# ADuCM410 register map
Vendor: Analog Devices; Series: ADuCM410; File version: 1p0
CPU: CM33 r0p1, little endian, MPU, FPU, 3 interrupt priority bits
Registers are 32-bit, read-write, reset 0x0 unless marked. A register's access mark holds for its fields unless they carry their own. Offsets are from the block's base; [hi:lo] are bit positions; {n}, {i} and the like mark numbered series; 'fields as' and 'values as' point back to an identical list.

## DMAREQ
Base 0x40007000
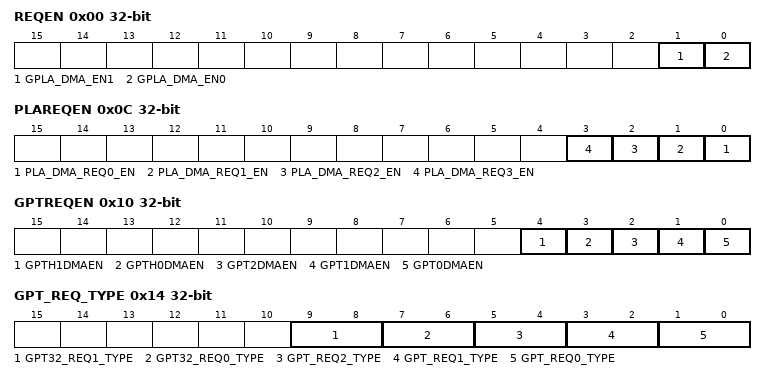
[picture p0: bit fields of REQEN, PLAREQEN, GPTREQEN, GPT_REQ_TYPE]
0x00 REQEN — GPT/GPT32 and PLA DMA Request Enable
  [1] GPLA_DMA_EN1 range 0x00000000..0x00000001 — GPT/GPT32 and PLA DMA Request 1 Enable
  [0] GPLA_DMA_EN0 range 0x00000000..0x00000001 — GPT/GPT32 and PLA DMA Request 0 Enable
0x04 REQ0SEL — GPT/GPT32 and PLA DMA Request 0 Select
  [3:0] DMA_REQ0_SEL — GPT/GPT32 and PLA DMA Request 0 Source Select
    {v}=PLA_REQ{v} (PLA DMA Request {v}) (v=0..3); 4=GPT_REQ0 (GPT 0 DMA Request); 5=GPT_REQ1 (GPT 1 DMA Request); 6=GPT_REQ2 (GPT 2 DMA Request); 7=GPt32_REQ0 (GPT32 0 DMA Request); 8=GPT32_REQ1 (GPT32 1 DMA Request)
0x08 REQ1SEL — GPT/GPT32 and PLA DMA Request 1 Select
  [3:0] DMA_REQ1_SEL — GPT/GPT32 and PLA DMA Request 1 Source Select
    values as REQ0SEL.DMA_REQ0_SEL
0x0C PLAREQEN — PLA DMA Requests Enable
  [n] PLA_DMA_REQ{n}_EN range 0x00000000..0x00000001 (n=0..3) — PLA DMA Request {n} Enable
0x10 GPTREQEN — GPT/GPT32 DMA Requests Enable
  [4] GPTH1DMAEN range 0x00000000..0x00000001 — GPT32 1 DMA Request Enable
  [3] GPTH0DMAEN range 0x00000000..0x00000001 — GPT32 0 DMA Request Enable
  [2] GPT2DMAEN range 0x00000000..0x00000001 — GPT 2 DMA Request Enable
  [1] GPT1DMAEN range 0x00000000..0x00000001 — GPT 1 DMA Request Enable
  [0] GPT0DMAEN range 0x00000000..0x00000001 — GPT 0 DMA Request Enable
0x14 GPT_REQ_TYPE — GPT and GPT32 Require Type
  [all] fields
    0=High Level Trigger Interrupt and High Level Trigger DMA Request; 1=Rising Edge Trigger Interrupt and Rising Edge Trigger DMA Request; 2=Low Level Trigger Interrupt and Low Level Trigger DMA Request; 3=Falling Edge Trigger Interrupt and Falling Edge Trigger DMA Request
  [9:8] GPT32_REQ1_TYPE — GPT32 Req1 DMA Require Type
  [7:6] GPT32_REQ0_TYPE — GPT32 Req0 DMA Require Type
  [5:4] GPT_REQ2_TYPE — GPT Req2 DMA Require Type
  [3:2] GPT_REQ1_TYPE — GPT Req1 DMA Require Type
  [1:0] GPT_REQ0_TYPE — GPT Req0 DMA Require Type

## MDIO
Base 0x40022000
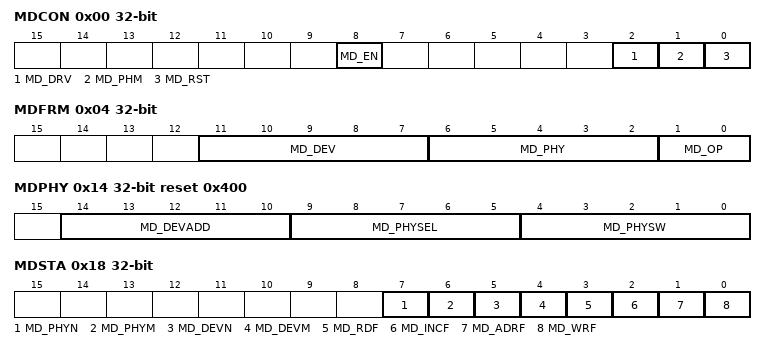
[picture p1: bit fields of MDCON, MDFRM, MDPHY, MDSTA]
0x00 MDCON — MDIO Block Control
  [8] MD_EN range 0x00000000..0x00000001 — MD Enable
  [2] MD_DRV — Enable Open-drain or Push-pull of MDIO Drive
    0=MD_DRV_OD (MDIO Drive Open Drain.); 1=MD_DRV_PP (MDIO Drive Push-pull.)
  [1] MD_PHM — Enable PHY Address Bit Width
    0=EN_5bit (5bits PHYADD is active); 1=EN_3bits (3bits PHYADD is active, two MSBS are ignored)
  [0] MD_RST wo — Write 1 to Reset MDIO Block.
    0=RSTINACTIVE (Reset MDIO); 1=RSTACTIVE (Reset MDIO)
0x04 MDFRM — MDIO Received Frame Control Information
  [11:7] MD_DEV ro — Received DEVADD
  [6:2] MD_PHY ro — Received PHYADR.
  [1:0] MD_OP ro — Received OP
    0=MD_OP_ADF (Address Frame.); 1=MD_OP_WRF (Write Frame.); 2=MD_OP_INCF (PostReadIncAdd Frame.); 3=MD_OP_RDF (Read Frame.)
0x08 MDRXD — MDIO Received Data
  [15:0] MD_RXD ro — Received Data
0x0C MDADR — MDIO Received Address
  [15:0] MD_ADR ro — Received Address
0x10 MDTXD — MDIO Data for Transmission
  [15:0] MD_TXD range 0x00000000..0x0000FFFF — TX Data
0x14 MDPHY reset 0x400 — MDIO PHYADDR Software Values and Selection and DEVADD
  [14:10] MD_DEVADD range 0x00000000..0x0000001F — Expected DEVADD
  [9:5] MD_PHYSEL range 0x00000000..0x0000001F — Selects Expected PHYADR Bits
  [4:0] MD_PHYSW range 0x00000000..0x0000001F — Software Provided PHYADR
0x18 MDSTA — MDIO Progress Signaling Through Frame
  [7] MD_PHYN ro — PHY Address Non Matching Status
  [6] MD_PHYM ro — PHY Address Matching Status
  [5] MD_DEVN ro — Device Address None Match Status
  [4] MD_DEVM ro — Device Address Matching Status
  [3] MD_RDF ro — Read Frame Status
  [2] MD_INCF ro — Post Read Increment Address Frame Status
  [1] MD_ADRF ro — Address Frame Status
  [0] MD_WRF ro — Write Frame Status
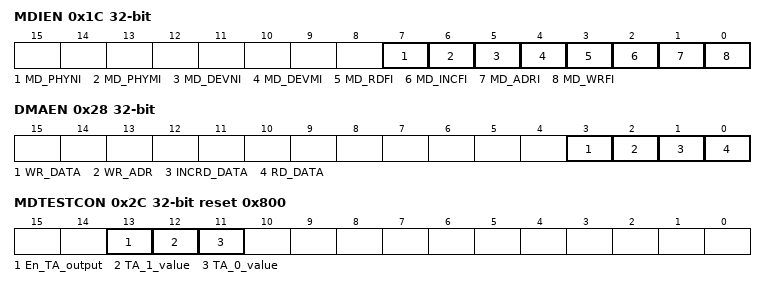
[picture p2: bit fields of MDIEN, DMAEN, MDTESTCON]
0x1C MDIEN — MDIO Interrupt Enables
  [7] MD_PHYNI range 0x00000000..0x00000001 — Interrupt Enable for MD_PHYN
  [6] MD_PHYMI range 0x00000000..0x00000001 — Interrupt Enable for MD_PHYM
  [5] MD_DEVNI range 0x00000000..0x00000001 — Interrupt Enable for MD_DEVN
  [4] MD_DEVMI range 0x00000000..0x00000001 — Interrupt Enable for MD_DEVM
  [3] MD_RDFI range 0x00000000..0x00000001 — Interrupt Enable for MD_RDF
  [2] MD_INCFI range 0x00000000..0x00000001 — Interrupt Enable for MD_INCF
  [1] MD_ADRI range 0x00000000..0x00000001 — Interrupt Enable for MD_ADRF
  [0] MD_WRFI range 0x00000000..0x00000001 — Interrupt Enable for MD_WRF
0x20 MDPIN — MDIO Read PHYADDR Pins
  [4:0] MD_PIN ro — PRTADR Pins
0x28 DMAEN — MDIO DMA Enable
  [3] WR_DATA range 0x00000000..0x00000001 — Write Data
  [2] WR_ADR range 0x00000000..0x00000001 — Write Address
  [1] INCRD_DATA range 0x00000000..0x00000001 — Increment Read Data
  [0] RD_DATA range 0x00000000..0x00000001 — Read Data
0x2C MDTESTCON reset 0x800 — MDIO Test Controller Protected by Test Key
  [13] En_TA_output range 0x00000000..0x00000001 — Enable Output Different During OP Phase
  [12] TA_1_value range 0x00000000..0x00000001 — Output Value During Second Bit of OP
  [11] TA_0_value range 0x00000000..0x00000001 — Output Value During First Bit of OP
